# CY8C4247AZI_M485 register map
File version: 0.1
PSoC 4200M
Registers are 32-bit, read-write, no defined reset value unless marked. A register's access mark holds for its fields unless they carry their own. Offsets are from the block's base; lines under a group give offsets from that group; [hi:lo] are bit positions; {n}, {i} and the like mark numbered series; 'fields as' and 'values as' point back to an identical list; <NAME> marks a mode.

## Memory map
0x00000000 I2C — Serial Communication Block
0x00000000 DMAC — DMAC Registers
0x00000000 UART — Serial Communication Block
0x00000000 Timer
0x00000000 PWM_2
0x00000000 PWM_0
0x00000000 PWM_1
0x00000000 ADC_3_Buffer — OpAmp
0x00000000 ADC — Sequencing SAR ADC
0x00000000 ADC_2_Buffer — OpAmp
0x00000000 CapSense_IDAC1 — IDAC
0x00000000 CapSense_IDAC2 — IDAC
0x00000000 SPI — Serial Communication Block
0x00000000 Comp_0 — Low Power Comparator
0x00000000 Comp_1 — Low Power Comparator

## Timer
Base 0x00000000
0x40200148 COUNTER — Current counter value
0x4020014C CC — Compare / capture value
0x40200150 CC_BUF — Compare / capture buffer value
0x40200154 PERIOD — Period value
0x40200158 PERIOD_BUF — Period buffer value

## PWM_2
Base 0x00000000
0x40200108 COUNTER — Current counter value
0x4020010C CC — Compare / capture value
0x40200110 CC_BUF — Compare / capture buffer value
0x40200114 PERIOD — Period value
0x40200118 PERIOD_BUF — Period buffer value

## PWM_0
Base 0x00000000
0x40200188 COUNTER — Current counter value
0x4020018C CC — Compare / capture value
0x40200190 CC_BUF — Compare / capture buffer value
0x40200194 PERIOD — Period value
0x40200198 PERIOD_BUF — Period buffer value

## PWM_1
Base 0x00000000
0x402001C8 COUNTER — Current counter value
0x402001CC CC — Compare / capture value
0x402001D0 CC_BUF — Compare / capture buffer value
0x402001D4 PERIOD — Period value
0x402001D8 PERIOD_BUF — Period buffer value

## ADC_3_Buffer — OpAmp
Base 0x00000000
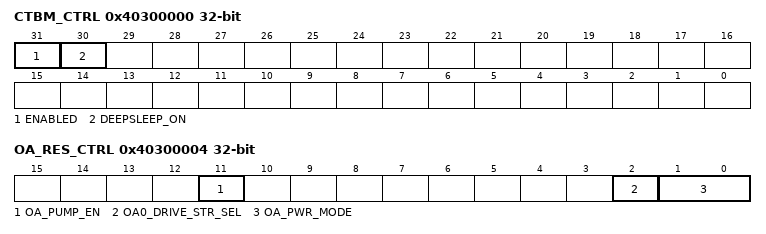
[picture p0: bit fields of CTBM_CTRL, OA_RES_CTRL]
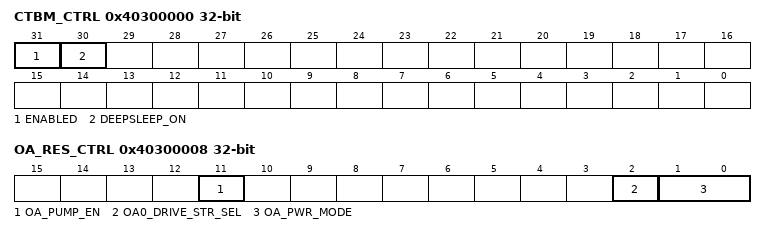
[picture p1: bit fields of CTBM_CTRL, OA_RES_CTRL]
0x40300000 CTBM_CTRL — Global CTB IP and power control
  [31] ENABLED — Selects component behavior in DeepSleep power mode
    0=DISABLE (CTB IP disabled (put analog in power down, open all switches)); 1=ENABLE (CTB IP enabledCTB IP enabled)
  [30] DEEPSLEEP_ON — Selects component behavior in DeepSleep power mode
    0=DISABLE (CTB IP disabled off during DeepSleep power mode); 1=ENABLE (CTB IP remains enabled during DeepSleep power mode (if ENABLED=1))
0x40300004 OA_RES_CTRL — Opamp and resistor control
  [11] OA_PUMP_EN — Selects pump
    0=DISABLE (Pump disabled); 1=ENABLE (Pump enabled)
  [2] OA0_DRIVE_STR_SEL — Opamp output strenght select
    0=Cy1x (Internal only); 1=Cy10x (Output to pin)
  [1:0] OA_PWR_MODE — Selects power for opamp
    0=OFF; 1=LOW (Low power); 2=MED (Medium power); 3=HIGH (High power)
0x40300F08 OA_COMP_TRIM — Opamp Compenation Capacitor Trim
  [1:0] OA_COMP_TRIM
    1=HIGH_SPEED; 2=BALANCED; 3=HIGH_STABILITY

## ADC_2_Buffer — OpAmp
Base 0x00000000
0x40300000 CTBM_CTRL — Global CTB IP and power control
  [31] ENABLED — Selects component behavior in DeepSleep power mode
    0=DISABLE (CTB IP disabled (put analog in power down, open all switches)); 1=ENABLE (CTB IP enabledCTB IP enabled)
  [30] DEEPSLEEP_ON — Selects component behavior in DeepSleep power mode
    0=DISABLE (CTB IP disabled off during DeepSleep power mode); 1=ENABLE (CTB IP remains enabled during DeepSleep power mode (if ENABLED=1))
0x40300008 OA_RES_CTRL — Opamp and resistor control
  [11] OA_PUMP_EN — Selects pump
    0=DISABLE (Pump disabled); 1=ENABLE (Pump enabled)
  [2] OA0_DRIVE_STR_SEL — Opamp output strenght select
    0=Cy1x (Internal only); 1=Cy10x (Output to pin)
  [1:0] OA_PWR_MODE — Selects power for opamp
    0=OFF; 1=LOW (Low power); 2=MED (Medium power); 3=HIGH (High power)
0x40300F14 OA_COMP_TRIM — Opamp Compenation Capacitor Trim
  [1:0] OA_COMP_TRIM
    1=HIGH_SPEED; 2=BALANCED; 3=HIGH_STABILITY

## CapSense_IDAC1 — IDAC
Base 0x00000000
Same registers: CapSense_IDAC2 0x00000000
0x40280004 CSD_IDAC_POLARITY
0x40280008 CSD_IDAC
0x4028FF00 CSD_TRIM1 — CSD IDAC TRIM1
0x4028FF04 CSD_TRIM2 — CSD IDAC TRIM2
